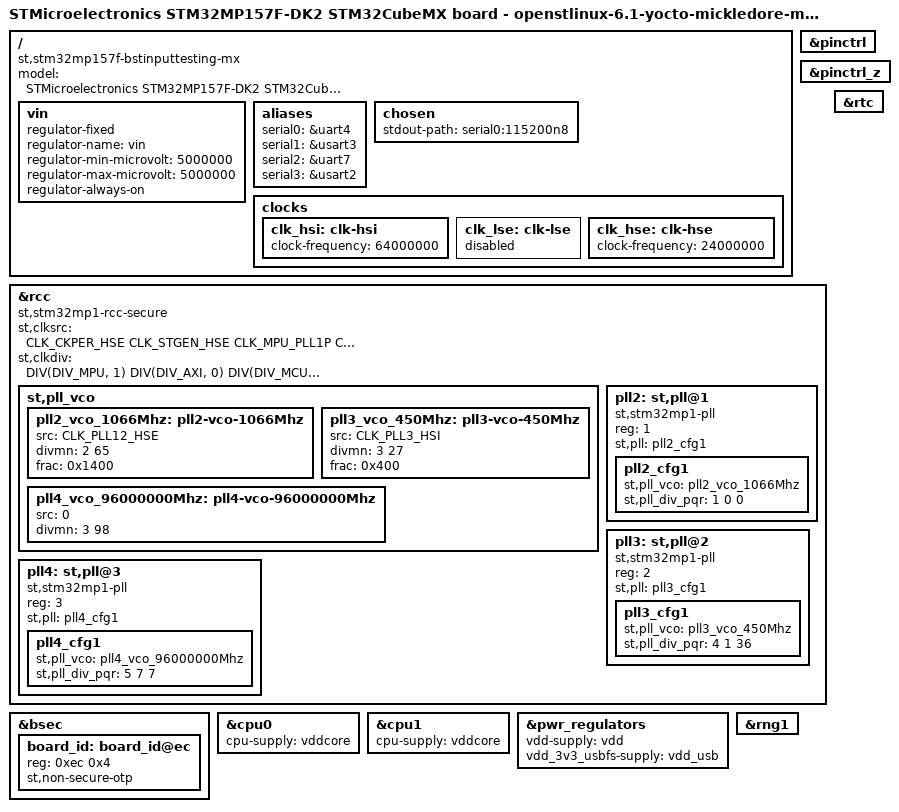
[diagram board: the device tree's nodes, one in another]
// SPDX-License-Identifier: (GPL-2.0-or-later OR BSD-3-Clause)
/*
 * Copyright (C) 2024, STMicroelectronics - All Rights Reserved
 * Author: STM32CubeMX code generation for STMicroelectronics.
 */

/* For more information on Device Tree configuration, please refer to
 * https://wiki.st.com/stm32mpu/wiki/Category:Device_tree_configuration
 */

/dts-v1/;

#include <dt-bindings/pinctrl/stm32-pinfunc.h>
#include <dt-bindings/clock/stm32mp1-clksrc.h>

#include "stm32mp157.dtsi"
#include "stm32mp15xf.dtsi"
#include "stm32mp15xxac-pinctrl.dtsi"
/* !!! log : Warning - DDR not configured: unknown DDR dtsi  !!! */
/*#include "???-ddr.dtsi"*/

/* USER CODE BEGIN includes */
#include "stm32mp15-pinctrl.dtsi"
/* USER CODE END includes */

/ {
	model = "STMicroelectronics STM32MP157F-DK2 STM32CubeMX board - openstlinux-6.1-yocto-mickledore-mpu-v24.06.26";
	compatible = "st,stm32mp157f-bstinputtesting-mx", "st,stm32mp157f-dk2", "st,stm32mp157";

	/* !!! log : Warning - no DDR config found: 'memory' node not generated  !!! */

	/*
	memory@??? {
		reg = < ??? >;
	};
	*/

	/* USER CODE BEGIN root */

	vin:vin{
		compatible = "regulator-fixed";
		regulator-name = "vin";
		regulator-min-microvolt = <5000000>;
		regulator-max-microvolt = <5000000>;
		regulator-always-on;
	};

	aliases{
		serial0 = &uart4;
		serial1 = &usart3;
		serial2 = &uart7;
		serial3 = &usart2;
	};

	chosen{
		stdout-path = "serial0:115200n8";
	};
	/* USER CODE END root */

	clocks {
		/* USER CODE BEGIN clocks */
		/* USER CODE END clocks */

		clk_hsi: clk-hsi {
			clock-frequency = <64000000>;

			/* USER CODE BEGIN clk_hsi */
			/* USER CODE END clk_hsi */
		};
		clk_lse: clk-lse {
			status = "disabled";

			/* USER CODE BEGIN clk_lse */
			/* USER CODE END clk_lse */
		};
		clk_hse: clk-hse {
			clock-frequency = <24000000>;

			/* USER CODE BEGIN clk_hse */
			/* USER CODE END clk_hse */
		};
	};

}; /*root*/

&pinctrl {
	/* USER CODE BEGIN pinctrl */
	/* USER CODE END pinctrl */
};

&pinctrl_z {
	/* USER CODE BEGIN pinctrl_z */
	/* USER CODE END pinctrl_z */
};

&rcc{
	status = "okay";

	/* USER CODE BEGIN rcc */
	compatible = "st,stm32mp1-rcc-secure", "st,stm32mp1-rcc", "syscon";
	/* USER CODE END rcc */

	st,clksrc = <
		CLK_CKPER_HSE
		CLK_STGEN_HSE
		CLK_MPU_PLL1P
		CLK_AXI_PLL2P
		CLK_MCU_PLL3P
	>;
	st,clkdiv = <
		DIV(DIV_MPU, 1)
		DIV(DIV_AXI, 0)
		DIV(DIV_MCU, 0)
		DIV(DIV_APB1, 1)
		DIV(DIV_APB2, 1)
		DIV(DIV_APB3, 1)
		DIV(DIV_APB4, 1)
		DIV(DIV_APB5, 2)
		DIV(DIV_RTC, 23)
		DIV(DIV_MCO1, 0)
		DIV(DIV_MCO2, 0)
	>;
	st,pll_vco {
		pll2_vco_1066Mhz: pll2-vco-1066Mhz {
			src = < CLK_PLL12_HSE >;
			divmn = < 2 65 >;
			frac = < 0x1400 >;
		};
		pll3_vco_450Mhz: pll3-vco-450Mhz {
			src = < CLK_PLL3_HSI >;
			divmn = < 3 27 >;
			frac = < 0x400 >;
		};
		pll4_vco_96000000Mhz: pll4-vco-96000000Mhz {
			src = < 0 >;
			divmn = < 3 98 >;
		};
		/* USER CODE BEGIN rcc_st-pll_vco */
		/* USER CODE END rcc_st-pll_vco */
	};

	pll2:st,pll@1 {
		compatible = "st,stm32mp1-pll";
		reg = <1>;

		st,pll = < &pll2_cfg1 >;

		pll2_cfg1: pll2_cfg1 {
			st,pll_vco = < &pll2_vco_1066Mhz >;
			st,pll_div_pqr = < 1 0 0 >;
		};
		/* USER CODE BEGIN pll2 */
		/* USER CODE END pll2 */
	};

	pll3:st,pll@2 {
		compatible = "st,stm32mp1-pll";
		reg = <2>;

		st,pll = < &pll3_cfg1 >;

		pll3_cfg1: pll3_cfg1 {
			st,pll_vco = < &pll3_vco_450Mhz >;
			st,pll_div_pqr = < 4 1 36 >;
		};
		/* USER CODE BEGIN pll3 */
		/* USER CODE END pll3 */
	};

	pll4:st,pll@3 {
		compatible = "st,stm32mp1-pll";
		reg = <3>;

		st,pll = < &pll4_cfg1 >;

		pll4_cfg1: pll4_cfg1 {
			st,pll_vco = < &pll4_vco_96000000Mhz >;
			st,pll_div_pqr = < 5 7 7 >;
		};
		/* USER CODE BEGIN pll4 */
		/* USER CODE END pll4 */
	};

};

/* USER CODE BEGIN addons */

&bsec{

	board_id:board_id@ec{
		reg = <0xec 0x4>;
		st,non-secure-otp;
	};
};

&cpu0{
	cpu-supply = <&vddcore>;
};

&cpu1{
	cpu-supply = <&vddcore>;
};

&pwr_regulators{
	vdd-supply = <&vdd>;
	vdd_3v3_usbfs-supply = <&vdd_usb>;
};

&rng1{
	status = "okay";
};

&rtc{
	status = "okay";
};
/* USER CODE END addons */

